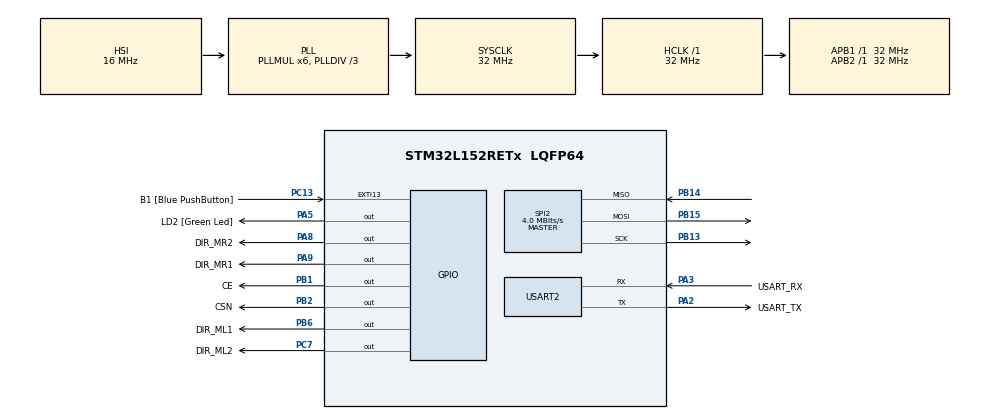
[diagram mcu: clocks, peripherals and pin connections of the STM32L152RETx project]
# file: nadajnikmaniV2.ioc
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Dma.Request0=USART2_RX
Dma.Request1=SPI2_TX
Dma.SPI2_TX.1.Direction=DMA_MEMORY_TO_PERIPH
Dma.SPI2_TX.1.Instance=DMA1_Channel5
Dma.SPI2_TX.1.MemDataAlignment=DMA_MDATAALIGN_HALFWORD
Dma.SPI2_TX.1.MemInc=DMA_MINC_ENABLE
Dma.SPI2_TX.1.Mode=DMA_NORMAL
Dma.SPI2_TX.1.PeriphDataAlignment=DMA_PDATAALIGN_HALFWORD
Dma.SPI2_TX.1.PeriphInc=DMA_PINC_DISABLE
Dma.SPI2_TX.1.Priority=DMA_PRIORITY_LOW
Dma.USART2_RX.0.Direction=DMA_PERIPH_TO_MEMORY
Dma.USART2_RX.0.Instance=DMA1_Channel6
Dma.USART2_RX.0.MemDataAlignment=DMA_MDATAALIGN_BYTE
Dma.USART2_RX.0.MemInc=DMA_MINC_ENABLE
Dma.USART2_RX.0.Mode=DMA_NORMAL
Dma.USART2_RX.0.PeriphDataAlignment=DMA_PDATAALIGN_BYTE
Dma.USART2_RX.0.PeriphInc=DMA_PINC_DISABLE
Dma.USART2_RX.0.Priority=DMA_PRIORITY_LOW
Mcu.Family=STM32L1
Mcu.Name=STM32L152RETx
Mcu.Package=LQFP64
NVIC.DMA1_Channel5_IRQn=true\:0\:0\:false\:true\:true\:3\:false\:true\:true
NVIC.DMA1_Channel6_IRQn=true\:0\:0\:false\:true\:true\:2\:false\:true\:true
NVIC.PriorityGroup=NVIC_PRIORITYGROUP_0
NVIC.USART2_IRQn=true\:0\:0\:false\:true\:true\:1\:true\:true\:true
PA13.GPIO_Label=TMS
PA13.Mode=Serial_Wire
PA13.Signal=SYS_JTMS-SWDIO
PA14.GPIO_Label=TCK
PA14.Mode=Serial_Wire
PA14.Signal=SYS_JTCK-SWCLK
PA2.GPIO_Label=USART_TX
PA2.Mode=Asynchronous
PA2.Signal=USART2_TX
PA3.GPIO_Label=USART_RX
PA3.Mode=Asynchronous
PA3.Signal=USART2_RX
PA5.GPIO_Label=LD2 [Green Led]
PA5.Signal=GPIO_Output
PA8.GPIO_Label=DIR_MR2
PA8.Signal=GPIO_Output
PA9.GPIO_Label=DIR_MR1
PA9.Signal=GPIO_Output
PB1.GPIO_Label=CE
PB1.Signal=GPIO_Output
PB13.Mode=Full_Duplex_Master
PB13.Signal=SPI2_SCK
PB14.Mode=Full_Duplex_Master
PB14.Signal=SPI2_MISO
PB15.Mode=Full_Duplex_Master
PB15.Signal=SPI2_MOSI
PB2.GPIO_Label=CSN
PB2.Signal=GPIO_Output
PB3.GPIO_Label=SWO
PB3.Signal=SYS_JTDO-TRACESWO
PB6.GPIO_Label=DIR_ML1
PB6.Signal=GPIO_Output
PC13-WKUP2.GPIO_Label=B1 [Blue PushButton]
PC13-WKUP2.Signal=GPXTI13
PC14-OSC32_IN.Mode=LSE-External-Oscillator
PC14-OSC32_IN.Signal=RCC_OSC32_IN
PC15-OSC32_OUT.Mode=LSE-External-Oscillator
PC15-OSC32_OUT.Signal=RCC_OSC32_OUT
PC7.GPIO_Label=DIR_ML2
PC7.Signal=GPIO_Output
PH0-OSC_IN.Mode=HSE-External-Clock-Source
PH0-OSC_IN.Signal=RCC_OSC_IN
PH1-OSC_OUT.Signal=RCC_OSC_OUT
ProjectManager.HeapSize=0x200
ProjectManager.StackSize=0x400
ProjectManager.TargetToolchain=STM32CubeIDE
RCC.48MHZClocksFreq_Value=48000000
RCC.AHBFreq_Value=32000000
RCC.APB1Freq_Value=32000000
RCC.APB1TimFreq_Value=32000000
RCC.APB2Freq_Value=32000000
RCC.APB2TimFreq_Value=32000000
RCC.HCLKFreq_Value=32000000
RCC.HSE_VALUE=8000000
RCC.HSI_VALUE=16000000
RCC.MSI_VALUE=2097000
RCC.PLLDIV=RCC_PLL_DIV3
RCC.PLLMUL=RCC_PLL_MUL6
RCC.RTCClockSelectionVirtual=RCC_RTCCLKSOURCE_LSE
RCC.SYSCLKFreq_VALUE=32000000
RCC.SYSCLKSource=RCC_SYSCLKSOURCE_PLLCLK
RCC.USBOutput=48000000
RCC.VCOOutputFreq_Value=96000000
SPI2.BaudRatePrescaler=SPI_BAUDRATEPRESCALER_8
SPI2.CalculateBaudRate=4.0 MBits/s
SPI2.DataSize=SPI_DATASIZE_8BIT
SPI2.Direction=SPI_DIRECTION_2LINES
SPI2.Mode=SPI_MODE_MASTER
SPI2.VirtualType=VM_MASTER
USART2.VirtualMode=VM_ASYNC
board=NUCLEO-L152RE

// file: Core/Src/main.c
/* USER CODE BEGIN Header */
/**
  ******************************************************************************
  * @file           : main.c
  * @brief          : Main program body
  ******************************************************************************
  * @attention
  *
  * Copyright (c) 2024 STMicroelectronics.
  * All rights reserved.
  *
  * This software is licensed under terms that can be found in the LICENSE file
  * in the root directory of this software component.
  * If no LICENSE file comes with this software, it is provided AS-IS.
  *
  ******************************************************************************
  */
/* USER CODE END Header */
#include "main.h"
#include "dma.h"
#include "spi.h"
#include "usart.h"
#include "gpio.h"

/* USER CODE BEGIN Includes */
#include "nRF24_Defs.h"
#include "nRF24.h"
/* USER CODE END Includes */

/* USER CODE BEGIN PV */
uint8_t Buffer[15];
/* USER CODE END PV */

void SystemClock_Config(void);
static void MX_NVIC_Init(void);

int main(void)
{

  /* MCU Configuration--------------------------------------------------------*/

  /* Reset of all peripherals, Initializes the Flash interface and the Systick. */
  HAL_Init();

  /* Configure the system clock */
  SystemClock_Config();

  /* Initialize all configured peripherals */
  MX_GPIO_Init();
  MX_DMA_Init();
  MX_USART2_UART_Init();
  MX_SPI2_Init();

  /* Initialize interrupts */
  MX_NVIC_Init();
  /* USER CODE BEGIN 2 */
  HAL_UARTEx_ReceiveToIdle_DMA(&huart2, Buffer, 15);
  nRF24_SetRXAddress(0,"Nad");
  nRF24_SetTXAddress("Odb");
  nRF24_TX_Mode();
  /* USER CODE END 2 */

  /* Infinite loop */
  while (1)
  {
  	  nRF24_WriteTXPayload(Buffer);
  	  HAL_Delay(1);
  	  nRF24_WaitTX();
  	 // nRF24_WriteStatus((1<<NRF24_RX_DR)|(1<<NRF24_TX_DS)|(1<<NRF24_MAX_RT));
  }
}

void SystemClock_Config(void)
{
  RCC_OscInitTypeDef RCC_OscInitStruct = {0};
  RCC_ClkInitTypeDef RCC_ClkInitStruct = {0};

  /** Configure the main internal regulator output voltage
  */
  __HAL_PWR_VOLTAGESCALING_CONFIG(PWR_REGULATOR_VOLTAGE_SCALE1);

  /** Initializes the RCC Oscillators according to the specified parameters
  * in the RCC_OscInitTypeDef structure.
  */
  RCC_OscInitStruct.OscillatorType = RCC_OSCILLATORTYPE_HSI;
  RCC_OscInitStruct.HSIState = RCC_HSI_ON;
  RCC_OscInitStruct.HSICalibrationValue = RCC_HSICALIBRATION_DEFAULT;
  RCC_OscInitStruct.PLL.PLLState = RCC_PLL_ON;
  RCC_OscInitStruct.PLL.PLLSource = RCC_PLLSOURCE_HSI;
  RCC_OscInitStruct.PLL.PLLMUL = RCC_PLL_MUL6;
  RCC_OscInitStruct.PLL.PLLDIV = RCC_PLL_DIV3;
  if (HAL_RCC_OscConfig(&RCC_OscInitStruct) != HAL_OK)
  {
    Error_Handler();
  }

  /** Initializes the CPU, AHB and APB buses clocks
  */
  RCC_ClkInitStruct.ClockType = RCC_CLOCKTYPE_HCLK|RCC_CLOCKTYPE_SYSCLK
                              |RCC_CLOCKTYPE_PCLK1|RCC_CLOCKTYPE_PCLK2;
  RCC_ClkInitStruct.SYSCLKSource = RCC_SYSCLKSOURCE_PLLCLK;
  RCC_ClkInitStruct.AHBCLKDivider = RCC_SYSCLK_DIV1;
  RCC_ClkInitStruct.APB1CLKDivider = RCC_HCLK_DIV1;
  RCC_ClkInitStruct.APB2CLKDivider = RCC_HCLK_DIV1;

  if (HAL_RCC_ClockConfig(&RCC_ClkInitStruct, FLASH_LATENCY_1) != HAL_OK)
  {
    Error_Handler();
  }
}

/**
  * @brief NVIC Configuration.
  * @retval None
  */
static void MX_NVIC_Init(void)
{
  /* USART2_IRQn interrupt configuration */
  HAL_NVIC_SetPriority(USART2_IRQn, 0, 0);
  HAL_NVIC_EnableIRQ(USART2_IRQn);
  /* DMA1_Channel6_IRQn interrupt configuration */
  HAL_NVIC_SetPriority(DMA1_Channel6_IRQn, 0, 0);
  HAL_NVIC_EnableIRQ(DMA1_Channel6_IRQn);
  /* DMA1_Channel5_IRQn interrupt configuration */
  HAL_NVIC_SetPriority(DMA1_Channel5_IRQn, 0, 0);
  HAL_NVIC_EnableIRQ(DMA1_Channel5_IRQn);
}

/* USER CODE BEGIN 4 */
void HAL_UARTEx_RxEventCallback(UART_HandleTypeDef *huart, uint16_t Size)
{
	if (huart -> Instance == USART2)
	{
		HAL_GPIO_TogglePin(LD2_GPIO_Port, LD2_Pin);
		HAL_UARTEx_ReceiveToIdle_DMA(&huart2, Buffer, 15);
	}

}
/* USER CODE END 4 */

void Error_Handler(void)
{
  __disable_irq();
  while (1)
  {
  }
}
